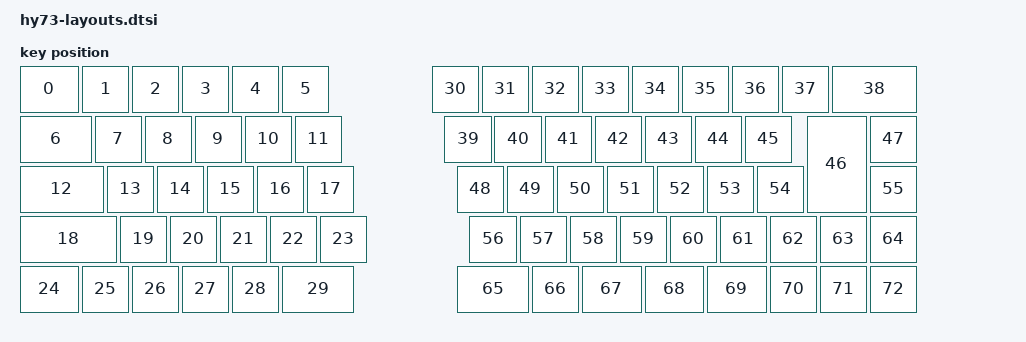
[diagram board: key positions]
#include <physical_layouts.dtsi>

/ {
    hy73_layout: hy73_layout {
        compatible = "zmk,physical-layout";
        display-name = "HY73 Split";

        keys =
            <&key_physical_attrs 125 100    0   0 0 0 0>,
            <&key_physical_attrs 100 100  125   0 0 0 0>,
            <&key_physical_attrs 100 100  225   0 0 0 0>,
            <&key_physical_attrs 100 100  325   0 0 0 0>,
            <&key_physical_attrs 100 100  425   0 0 0 0>,
            <&key_physical_attrs 100 100  525   0 0 0 0>,
            <&key_physical_attrs 150 100    0 100 0 0 0>,
            <&key_physical_attrs 100 100  150 100 0 0 0>,
            <&key_physical_attrs 100 100  250 100 0 0 0>,
            <&key_physical_attrs 100 100  350 100 0 0 0>,
            <&key_physical_attrs 100 100  450 100 0 0 0>,
            <&key_physical_attrs 100 100  550 100 0 0 0>,
            <&key_physical_attrs 175 100    0 200 0 0 0>,
            <&key_physical_attrs 100 100  175 200 0 0 0>,
            <&key_physical_attrs 100 100  275 200 0 0 0>,
            <&key_physical_attrs 100 100  375 200 0 0 0>,
            <&key_physical_attrs 100 100  475 200 0 0 0>,
            <&key_physical_attrs 100 100  575 200 0 0 0>,
            <&key_physical_attrs 200 100    0 300 0 0 0>,
            <&key_physical_attrs 100 100  200 300 0 0 0>,
            <&key_physical_attrs 100 100  300 300 0 0 0>,
            <&key_physical_attrs 100 100  400 300 0 0 0>,
            <&key_physical_attrs 100 100  500 300 0 0 0>,
            <&key_physical_attrs 100 100  600 300 0 0 0>,
            <&key_physical_attrs 125 100    0 400 0 0 0>,
            <&key_physical_attrs 100 100  125 400 0 0 0>,
            <&key_physical_attrs 100 100  225 400 0 0 0>,
            <&key_physical_attrs 100 100  325 400 0 0 0>,
            <&key_physical_attrs 100 100  425 400 0 0 0>,
            <&key_physical_attrs 150 100  525 400 0 0 0>,
            <&key_physical_attrs 100 100  825   0 0 0 0>,
            <&key_physical_attrs 100 100  925   0 0 0 0>,
            <&key_physical_attrs 100 100 1025   0 0 0 0>,
            <&key_physical_attrs 100 100 1125   0 0 0 0>,
            <&key_physical_attrs 100 100 1225   0 0 0 0>,
            <&key_physical_attrs 100 100 1325   0 0 0 0>,
            <&key_physical_attrs 100 100 1425   0 0 0 0>,
            <&key_physical_attrs 100 100 1525   0 0 0 0>,
            <&key_physical_attrs 175 100 1625   0 0 0 0>,
            <&key_physical_attrs 100 100  850 100 0 0 0>,
            <&key_physical_attrs 100 100  950 100 0 0 0>,
            <&key_physical_attrs 100 100 1050 100 0 0 0>,
            <&key_physical_attrs 100 100 1150 100 0 0 0>,
            <&key_physical_attrs 100 100 1250 100 0 0 0>,
            <&key_physical_attrs 100 100 1350 100 0 0 0>,
            <&key_physical_attrs 100 100 1450 100 0 0 0>,
            <&key_physical_attrs 125 200 1575 100 0 0 0>,
            <&key_physical_attrs 100 100 1700 100 0 0 0>,
            <&key_physical_attrs 100 100  875 200 0 0 0>,
            <&key_physical_attrs 100 100  975 200 0 0 0>,
            <&key_physical_attrs 100 100 1075 200 0 0 0>,
            <&key_physical_attrs 100 100 1175 200 0 0 0>,
            <&key_physical_attrs 100 100 1275 200 0 0 0>,
            <&key_physical_attrs 100 100 1375 200 0 0 0>,
            <&key_physical_attrs 100 100 1475 200 0 0 0>,
            <&key_physical_attrs 100 100 1700 200 0 0 0>,
            <&key_physical_attrs 100 100  900 300 0 0 0>,
            <&key_physical_attrs 100 100 1000 300 0 0 0>,
            <&key_physical_attrs 100 100 1100 300 0 0 0>,
            <&key_physical_attrs 100 100 1200 300 0 0 0>,
            <&key_physical_attrs 100 100 1300 300 0 0 0>,
            <&key_physical_attrs 100 100 1400 300 0 0 0>,
            <&key_physical_attrs 100 100 1500 300 0 0 0>,
            <&key_physical_attrs 100 100 1600 300 0 0 0>,
            <&key_physical_attrs 100 100 1700 300 0 0 0>,
            <&key_physical_attrs 150 100  875 400 0 0 0>,
            <&key_physical_attrs 100 100 1025 400 0 0 0>,
            <&key_physical_attrs 125 100 1125 400 0 0 0>,
            <&key_physical_attrs 125 100 1250 400 0 0 0>,
            <&key_physical_attrs 125 100 1375 400 0 0 0>,
            <&key_physical_attrs 100 100 1500 400 0 0 0>,
            <&key_physical_attrs 100 100 1600 400 0 0 0>,
            <&key_physical_attrs 100 100 1700 400 0 0 0>;
    };
};
